# STM32F407 register map
File version: 1.2
CPU: CM4 r1p0, little endian, no MPU, no FPU, 4 interrupt priority bits
Registers are 32-bit, read-write, reset 0x0 unless marked. A register's access mark holds for its fields unless they carry their own. Offsets are from the block's base; [hi:lo] are bit positions.

## SPI1 — Serial peripheral interface
Base 0x40013000
Same registers: I2S2ext 0x40003400, SPI2 0x40003800, SPI3 0x40003C00, I2S3ext 0x40004000, SPI4 0x40013400, SPI5 0x40015000, SPI6 0x40015400
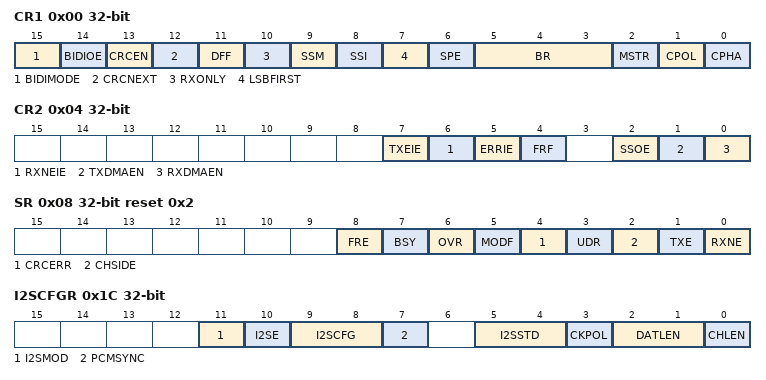
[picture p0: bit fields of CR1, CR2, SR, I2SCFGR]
0x00 CR1 — control register 1
  [15] BIDIMODE — Bidirectional data mode enable
    0=Unidirectional (2-line unidirectional data mode selected); 1=Bidirectional (1-line bidirectional data mode selected)
  [14] BIDIOE — Output enable in bidirectional mode
    0=Output disabled (receive-only mode); 1=Output enabled (transmit-only mode)
  [13] CRCEN — Hardware CRC calculation enable
    0=Disabled (CRC calculation disabled); 1=Enabled (CRC calculation enabled)
  [12] CRCNEXT — CRC transfer next
    0=TxBuffer (Next transmit value is from Tx buffer); 1=CRC (Next transmit value is from Tx CRC register)
  [11] DFF — Data frame format
    0=EightBit (8-bit data frame format is selected for transmission/reception); 1=SixteenBit (16-bit data frame format is selected for transmission/reception)
  [10] RXONLY — Receive only
    0=Full duplex (Transmit and receive); 1=Output disabled (Receive-only mode)
  [9] SSM — Software slave management
    0=Disabled (Software slave management disabled); 1=Enabled (Software slave management enabled)
  [8] SSI — Internal slave select
    0=SlaveSelected (0 is forced onto the NSS pin and the I/O value of the NSS pin is ignored); 1=SlaveNotSelected (1 is forced onto the NSS pin and the I/O value of the NSS pin is ignored)
  [7] LSBFIRST — Frame format
    0=MSBFirst (Data is transmitted/received with the MSB first); 1=LSBFirst (Data is transmitted/received with the LSB first)
  [6] SPE — SPI enable
    0=Disabled (Peripheral disabled); 1=Enabled (Peripheral enabled)
  [5:3] BR — Baud rate control
    0=Div2 (f_PCLK / 2); 1=Div4 (f_PCLK / 4); 2=Div8 (f_PCLK / 8); 3=Div16 (f_PCLK / 16); 4=Div32 (f_PCLK / 32); 5=Div64 (f_PCLK / 64); 6=Div128 (f_PCLK / 128); 7=Div256 (f_PCLK / 256)
  [2] MSTR — Master selection
    0=Slave configuration; 1=Master configuration
  [1] CPOL — Clock polarity
    0=IdleLow (CK to 0 when idle); 1=IdleHigh (CK to 1 when idle)
  [0] CPHA — Clock phase
    0=FirstEdge (The first clock transition is the first data capture edge); 1=SecondEdge (The second clock transition is the first data capture edge)
0x04 CR2 — control register 2
  [7] TXEIE — Tx buffer empty interrupt enable
    0=Masked (TXE interrupt masked); 1=NotMasked (TXE interrupt not masked)
  [6] RXNEIE — RX buffer not empty interrupt enable
    0=Masked (RXE interrupt masked); 1=NotMasked (RXE interrupt not masked)
  [5] ERRIE — Error interrupt enable
    0=Masked (Error interrupt masked); 1=NotMasked (Error interrupt not masked)
  [4] FRF — Frame format
    0=Motorola (SPI Motorola mode); 1=TI (SPI TI mode)
  [2] SSOE — SS output enable
    0=Disabled (SS output is disabled in master mode); 1=Enabled (SS output is enabled in master mode)
  [1] TXDMAEN — Tx buffer DMA enable
    0=Disabled (Tx buffer DMA disabled); 1=Enabled (Tx buffer DMA enabled)
  [0] RXDMAEN — Rx buffer DMA enable
    0=Disabled (Rx buffer DMA disabled); 1=Enabled (Rx buffer DMA enabled)
0x08 SR access per field reset 0x2 — status register
  [8] FRE ro — TI frame format error
    on read: 0=NoError (No frame format error); 1=Error (A frame format error occurred)
  [7] BSY ro — Busy flag
    on read: 0=NotBusy (SPI not busy); 1=Busy (SPI busy)
  [6] OVR ro — Overrun flag
    on read: 0=No overrun occurred; 1=Overrun occurred
  [5] MODF ro — Mode fault
    on read: 0=NoFault (No mode fault occurred); 1=Fault (Mode fault occurred)
  [4] CRCERR rw — CRC error flag
    0=Match (CRC value received matches the SPIx_RXCRCR value); 1=NoMatch (CRC value received does not match the SPIx_RXCRCR value)
  [3] UDR ro — Underrun flag
    on read: 0=No underrun occurred; 1=Underrun occurred
  [2] CHSIDE ro — Channel side
    0=Left (Channel left has to be transmitted or has been received); 1=Right (Channel right has to be transmitted or has been received)
  [1] TXE ro — Transmit buffer empty
    0=NotEmpty (Tx buffer not empty); 1=Empty (Tx buffer empty)
  [0] RXNE ro — Receive buffer not empty
    0=Empty (Rx buffer empty); 1=NotEmpty (Rx buffer not empty)
0x0C DR — data register
  [15:0] DR — Data register
0x10 CRCPR reset 0x7 — CRC polynomial register
  [15:0] CRCPOLY
0x14 RXCRCR ro — RX CRC register
  [15:0] RxCRC
0x18 TXCRCR ro — TX CRC register
  [15:0] TxCRC
0x1C I2SCFGR — I2S configuration register
  [11] I2SMOD — I2S mode selection
    0=SPI mode is selected; 1=I2S mode is selected
  [10] I2SE — I2S Enable
    0=Disabled (I2S peripheral is disabled); 1=Enabled (I2S peripheral is enabled)
  [9:8] I2SCFG — I2S configuration mode
    0=SlaveTx (Slave - transmit); 1=SlaveRx (Slave - receive); 2=MasterTx (Master - transmit); 3=MasterRx (Master - receive)
  [7] PCMSYNC — PCM frame synchronization
    0=Short frame synchronisation; 1=Long frame synchronisation
  [5:4] I2SSTD — I2S standard selection
    0=Philips (I2S Philips standard); 1=MSB (MSB justified standard); 2=LSB (LSB justified standard); 3=PCM (PCM standard)
  [3] CKPOL — Steady state clock polarity
    0=IdleLow (I2S clock inactive state is low level); 1=IdleHigh (I2S clock inactive state is high level)
  [2:1] DATLEN — Data length to be transferred
    0=SixteenBit (16-bit data length); 1=TwentyFourBit (24-bit data length); 2=ThirtyTwoBit (32-bit data length)
  [0] CHLEN — Channel length (number of bits per audio channel)
    0=SixteenBit (16-bit wide); 1=ThirtyTwoBit (32-bit wide)
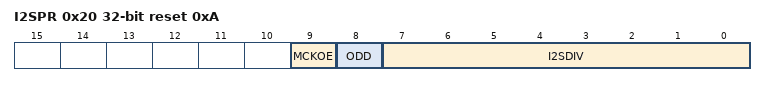
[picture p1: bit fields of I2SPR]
0x20 I2SPR reset 0xA — I2S prescaler register
  [9] MCKOE — Master clock output enable
    0=Disabled (Master clock output is disabled); 1=Enabled (Master clock output is enabled)
  [8] ODD — Odd factor for the prescaler
    0=Even (Real divider value is I2SDIV * 2); 1=Odd (Real divider value is (I2SDIV * 2) + 1)
  [7:0] I2SDIV range 2..255 — I2S Linear prescaler
